# RP2350 register map
Vendor: Raspberry Pi; File version: 0.1
CPU: CM33 r1p0, little endian, MPU, FPU, VTOR, 4 interrupt priority bits, 54 interrupts, 8 SAU regions
Registers are 32-bit, read-write, reset 0x0 unless marked. A register's access mark holds for its fields unless they carry their own. Offsets are from the block's base; [hi:lo] are bit positions; {n}, {i} and the like mark numbered series; 'fields as' and 'values as' point back to an identical list; <NAME> marks a mode.

## RISCV_CSR_BASE_FIXME — CSR listing for Hazard3
Base 0x00000000
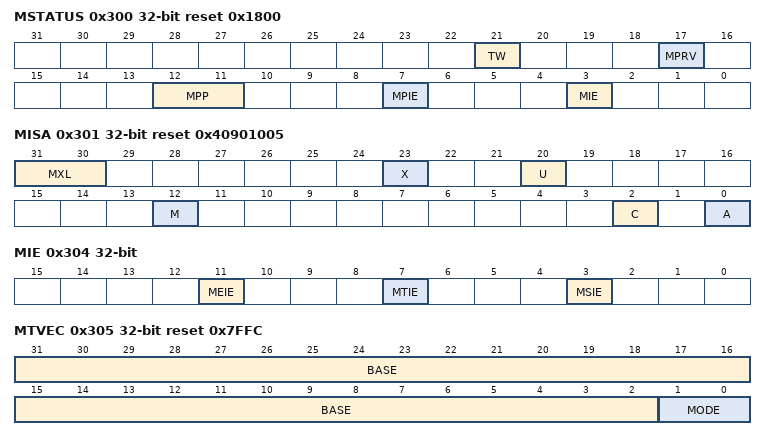
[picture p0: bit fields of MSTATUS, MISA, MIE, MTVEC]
0x300 MSTATUS reset 0x1800 — Machine status register
  [21] TW — Timeout wait. When 1, attempting to execute a WFI instruction in U-mode will instantly cause an illegal instruction exception.
  [17] MPRV — Modify privilege. If 1, loads and stores behave as though the current privilege level were `mpp`. This includes physical memory protection checks, and the privilege level asserted on the system bus alongside the load/store address.
  [12:11] MPP — Previous privilege level. Can store the values 3 (M-mode) or 0 (U-mode). If another value is written, hardware rounds to the nearest supported mode.
  [7] MPIE — Previous interrupt enable. Readable and writable. Is set to the current value of `mstatus.mie` on trap entry. Is set to 1 on trap return.
  [3] MIE — Interrupt enable. Readable and writable. Is set to 0 on trap entry. Is set to the current value of `mstatus.mpie` on trap return.
0x301 MISA ro reset 0x40901005 — Summary of ISA extension support . On RP2350, Hazard3's full `-march` string is: `rv32ima_zicsr_zifencei_zba_zbb_zbs_zbkb_zca_zcb_zcmp` . Note Zca is equivalent to the C extension in this case; all instructions from the RISC-V C extension relevant to a 32-bit non-floating-point processor are supported. On older toolchains which do not support the Zc extensions, the appropriate `-march` string is: `rv32imac_zicsr_zifencei_zba_zbb_zbs_zbkb` . In addition the following custom extensions are configured: Xh3bm, Xh3power, Xh3irq, Xh3pmpm
  [31:30] MXL — Value of 0x1 indicates this is a 32-bit processor.
  [23] X — Value of 1 indicates nonstandard extensions are present. (Xh3b bit manipulation, and custom sleep and interrupt control CSRs)
  [20] U — Value of 1 indicates U-mode is implemented.
  [12] M — Value of 1 indicates the M extension (integer multiply/divide) is implemented.
  [2] C — Value of 1 indicates the C extension (compressed instructions) is implemented.
  [0] A — Value of 1 indicates the A extension (atomics) is implemented.
0x302 MEDELEG — Machine exception delegation register. Not implemented, as no S-mode support.
0x303 MIDELEG — Machine interrupt delegation register. Not implemented, as no S-mode support.
0x304 MIE — Machine interrupt enable register
  [11] MEIE — External interrupt enable. The processor transfers to the external interrupt vector when `mie.meie`, `mip.meip` and `mstatus.mie` are all 1. . Hazard3 has internal registers to individually filter external interrupts (see `meiea`), but this standard control can be used to mask all external interrupts at once.
  [7] MTIE — Timer interrupt enable. The processor transfers to the timer interrupt vector when `mie.mtie`, `mip.mtip` and `mstatus.mie` are all 1, unless a software or external interrupt request is also valid at this time.
  [3] MSIE — Software interrupt enable. The processor transfers to the software interrupt vector `mie.msie`, `mip.msip` and `mstatus.mie` are all 1, unless an external interrupt request is also valid at this time.
0x305 MTVEC reset 0x7FFC — Machine trap handler base address.
  [31:2] BASE — The upper 30 bits of the trap vector address (2 LSBs are implicitly 0). Must be 64-byte-aligned if vectoring is enabled. Otherwise, must be 4-byte-aligned.
  [1:0] MODE — If 0 (direct mode), all traps set pc to the trap vector base. If 1 (vectored), exceptions set pc to the trap vector base, and interrupts set pc to 4 times the interrupt cause (3=soft IRQ, 7=timer IRQ, 11=external IRQ). . The upper bit is hardwired to zero, so attempting to set mode to 2 or 3 will result in a value of 0 or 1 respectively.
    0=Direct entry to mtvec; 1=Vectored entry to a 16-entry jump table starting at mtvec
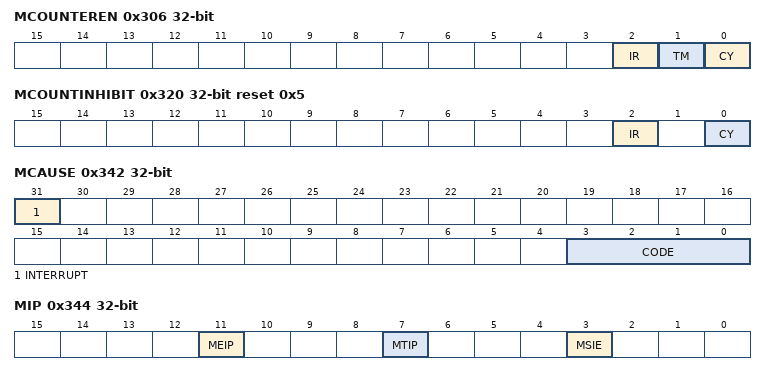
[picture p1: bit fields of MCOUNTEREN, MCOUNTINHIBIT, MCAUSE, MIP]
0x306 MCOUNTEREN — Counter enable. Control access to counters from U-mode. Not to be confused with mcountinhibit.
  [2] IR — If 1, U-mode is permitted to access the `instret`/`instreth` instruction retire counter CSRs. Otherwise, U-mode accesses to these CSRs will trap.
  [1] TM — No hardware effect, as the `time`/`timeh` CSRs are not implemented. However, this field still exists, as M-mode software can use it to track whether it should emulate U-mode attempts to access those CSRs.
  [0] CY — If 1, U-mode is permitted to access the `cycle`/`cycleh` cycle counter CSRs. Otherwise, U-mode accesses to these CSRs will trap.
0x30A MENVCFG ro — Machine environment configuration register, low half
  [0] FIOM — When set, fence instructions in modes less privileged than M-mode which specify that IO memory accesses are ordered will also cause ordering of main memory accesses. . FIOM is hardwired to zero on Hazard3, because S-mode is not supported, and because fence instructions execute as NOPs (with the exception of `fence.i`)
0x310 MSTATUSH ro — High half of mstatus, hardwired to 0.
0x31A MENVCFGH access not given — Machine environment configuration register, high half . This register is fully reserved, as Hazard3 does not implement the relevant extensions. It is implemented as hardwired-0.
0x320 MCOUNTINHIBIT reset 0x5 — Count inhibit register for `mcycle`/`minstret`
  [2] IR — Inhibit counting of the `minstret` and `minstreth` registers. Set by default to save power.
  [0] CY — Inhibit counting of the `mcycle` and `mcycleh` registers. Set by default to save power.
{0x320+i} MHPMEVENT{i} ro (i=3..31) — Extended performance event selector, hardwired to 0.
0x340 MSCRATCH — Scratch register for machine trap handlers. . 32-bit read/write register with no specific hardware function. Software may use this to do a fast save/restore of a core register in a trap handler.
0x341 MEPC — Machine exception program counter. . When entering a trap, the current value of the program counter is recorded here. When executing an `mret`, the processor jumps to `mepc`. Can also be read and written by software.
  [31:2] MEPC
0x342 MCAUSE — Machine trap cause. Set when entering a trap to indicate the reason for the trap. Readable and writable by software.
  [31] INTERRUPT — If 1, the trap was caused by an interrupt. If 0, it was caused by an exception.
  [3:0] CODE — If `interrupt` is set, `code` indicates the index of the bit in mip that caused the trap (3=soft IRQ, 7=timer IRQ, 11=external IRQ). Otherwise, `code` is set according to the cause of the exception.
    0=INSTR_ALIGN (Instruction fetch was misaligned. Will never fire on RP2350, since the C extension is enabled.); 1=INSTR_FAULT (Instruction access fault. Instruction fetch failed a PMP check, or encountered a downstream bus fault, and then passed the point of no speculation.); 2=ILLEGAL_INSTR (Illegal instruction was executed (including illegal CSR accesses)); 3=BREAKPOINT (Breakpoint. An ebreak instruction was executed when the relevant dcsr.ebreak bit was clear.); 4=LOAD_ALIGN (Load address misaligned. Hazard3 requires natural alignment of all accesses.); 5=LOAD_FAULT (Load access fault. A load failed a PMP check, or encountered a downstream bus error.); 6=STORE_ALIGN (Store/AMO address misaligned. Hazard3 requires natural alignment of all accesses.); 7=STORE_FAULT (Store/AMO access fault. A store/AMO failed a PMP check, or encountered a downstream bus error. Also set if an AMO is attempted on a region that does not support atomics (on RP2350, anything but SRAM).); 8=U_ECALL (Environment call from U-mode.); 11=M_ECALL (Environment call from M-mode.)
0x343 MTVAL ro — Machine bad address or instruction. Hardwired to zero.
0x344 MIP access per field — Machine interrupt pending
  [11] MEIP ro — External interrupt pending. The processor transfers to the external interrupt vector when `mie.meie`, `mip.meip` and `mstatus.mie` are all 1. . Hazard3 has internal registers to individually filter which external IRQs appear in `meip`. When `meip` is 1, this indicates there is at least one external interrupt which is asserted (hence pending in `mieipa`), enabled in `meiea`, and of priority greater than or equal to the current preemption level in `meicontext.preempt`.
  [7] MTIP rw — Timer interrupt pending. The processor transfers to the timer interrupt vector when `mie.mtie`, `mip.mtip` and `mstatus.mie` are all 1, unless a software or external interrupt request is also valid at this time.
  [3] MSIE rw — Software interrupt pending. The processor transfers to the software interrupt vector `mie.msie`, `mip.msip` and `mstatus.mie` are all 1, unless an external interrupt request is also valid at this time.
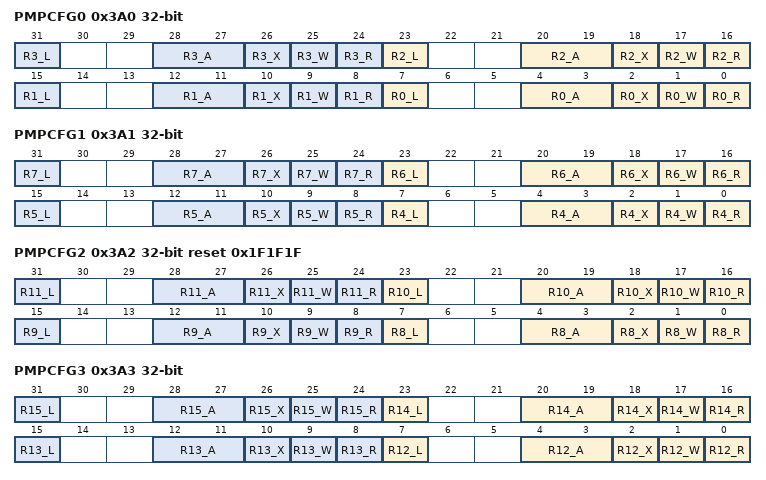
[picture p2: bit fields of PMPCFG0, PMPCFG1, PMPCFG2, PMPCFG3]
0x3A0 PMPCFG0 — Physical memory protection configuration for regions 0 through 3
  [8n+7] R{n}_L (n=0..3) — Lock region {n}, and apply it to M-mode as well as U-mode.
  [8n+4:8n+3] R{n}_A (n=0..3) — Address matching type for region {n}. Writing an unsupported value (TOR) will set the region to OFF.
    0=off (Disable region); 2=na4 (Naturally aligned 4-byte); 3=napot (Naturally aligned power-of-two (8 bytes to 4 GiB))
  [8n+2] R{n}_X (n=0..3) — Execute permission for region {n}
  [8n+1] R{n}_W (n=0..3) — Write permission for region {n}
  [8n] R{n}_R (n=0..3) — Read permission for region {n}
0x3A1 PMPCFG1 — Physical memory protection configuration for regions 4 through 7
  [8n-25] R{n}_L (n=4..7) — Lock region {n}, and apply it to M-mode as well as U-mode.
  [8n-28:8n-29] R{n}_A (n=4..7) — Address matching type for region {n}. Writing an unsupported value (TOR) will set the region to OFF.
    values as PMPCFG0.R0_A
  [8n-30] R{n}_X (n=4..7) — Execute permission for region {n}
  [8n-31] R{n}_W (n=4..7) — Write permission for region {n}
  [8n-32] R{n}_R (n=4..7) — Read permission for region {n}
0x3A2 PMPCFG2 ro reset 0x1F1F1F — Physical memory protection configuration for regions 8 through 11
  [8n-57] R{n}_L (n=8..11) — Lock region {n}, and apply it to M-mode as well as U-mode.
  [8n-60:8n-61] R{n}_A (n=8..11) — Address matching type for region {n}. Writing an unsupported value (TOR) will set the region to OFF.
    values as PMPCFG0.R0_A
  [8n-62] R{n}_X (n=8..11) — Execute permission for region {n}
  [8n-63] R{n}_W (n=8..11) — Write permission for region {n}
  [8n-64] R{n}_R (n=8..11) — Read permission for region {n}
0x3A3 PMPCFG3 ro — Physical memory protection configuration for regions 12 through 15
  [8n-89] R{n}_L (n=12..15) — Lock region {n}, and apply it to M-mode as well as U-mode.
  [8n-92:8n-93] R{n}_A (n=12..15) — Address matching type for region {n}. Writing an unsupported value (TOR) will set the region to OFF.
    values as PMPCFG0.R0_A
  [8n-94] R{n}_X (n=12..15) — Execute permission for region {n}
  [8n-95] R{n}_W (n=12..15) — Write permission for region {n}
  [8n-96] R{n}_R (n=12..15) — Read permission for region {n}
{0x3B0+i} PMPADDR{i} (i=0..7) — Physical memory protection address for region {i}. Note all PMP addresses are in units of four bytes.
  [29:0] PMPADDR{i}
0x3B8 PMPADDR8 ro reset 0x1FFFFFF — Physical memory protection address for region 8. Note all PMP addresses are in units of four bytes. . Hardwired to the address range `0x00000000` through `0x0fffffff`, which contains the boot ROM. This range is made accessible to User mode by default. User mode access to this range can be disabled using one of the dynamically configurable PMP regions, or using the permission registers in ACCESSCTRL.
  [29:0] PMPADDR8
0x3B9 PMPADDR9 ro reset 0x13FFFFFF — Physical memory protection address for region 9. Note all PMP addresses are in units of four bytes. . Hardwired to the address range `0x40000000` through `0x5fffffff`, which contains the system peripherals. This range is made accessible to User mode by default. User mode access to this range can be disabled using one of the dynamically configurable PMP regions, or using the permission registers in ACCESSCTRL.
  [29:0] PMPADDR9
0x3BA PMPADDR10 ro reset 0x35FFFFFF — Physical memory protection address for region 10. Note all PMP addresses are in units of four bytes. . Hardwired to the address range `0xd0000000` through `0xdfffffff`, which contains the core-local peripherals (SIO). This range is made accessible to User mode by default. User mode access to this range can be disabled using one of the dynamically configurable PMP regions, or using the permission registers in ACCESSCTRL.
  [29:0] PMPADDR10
{0x3B0+i} PMPADDR{i} ro (i=11..15) — Physical memory protection address for region {i}. Note all PMP addresses are in units of four bytes. . Hardwired to all-zeroes. This region is not implemented.
  [29:0] PMPADDR{i}
0x7A0 TSELECT — Select trigger to be configured via `tdata1`/`tdata2` . On RP2350, four instruction address triggers are implemented, so only the two LSBs of this register are writable.
  [1:0] TSELECT
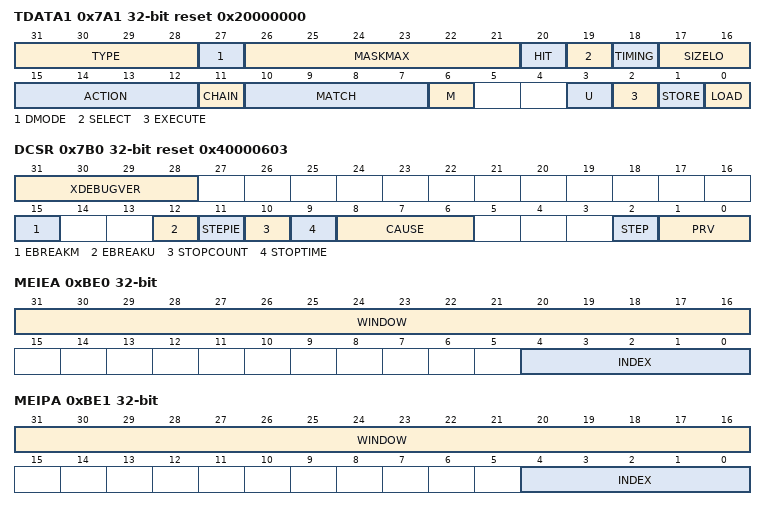
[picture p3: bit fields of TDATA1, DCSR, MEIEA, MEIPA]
0x7A1 TDATA1 access per field reset 0x20000000 — Trigger configuration data 1 . Hazard 3 only supports address/data match triggers (type=2) so this register description includes the `mcontrol` fields for this type. . More precisely, Hazard3 only supports exact instruction address match triggers (hardware breakpoints) so many of this register's fields are hardwired.
  [31:28] TYPE ro — Trigger type. Hardwired to type=2, meaning an address/data match trigger
  [27] DMODE rw — If 0, both Debug and M-mode can write the `tdata` registers at the selected `tselect`. . If 1, only Debug Mode can write the `tdata` registers at the selected `tselect`. Writes from other modes are ignored. . This bit is only writable from Debug Mode
  [26:21] MASKMAX ro — Value of 0 indicates only exact address matches are supported
  [20] HIT ro — Trigger hit flag. Not implemented, hardwired to 0.
  [19] SELECT ro — Hardwired value of 0 indicates that only address matches are supported, not data matches
  [18] TIMING ro — Hardwired value of 0 indicates that trigger fires before the triggering instruction executes, not afterward
  [17:16] SIZELO ro — Hardwired value of 0 indicates that access size matching is not supported
  [15:12] ACTION rw — Select action to be taken when the trigger fires.
    0=ebreak (Raise a breakpoint exception, which can be handled by the M-mode exception handler); 1=debug (Enter debug mode. This action is only selectable when `tdata1.dmode` is 1.)
  [11] CHAIN ro — Hardwired to 0 to indicate trigger chaining is not supported.
  [10:7] MATCH ro — Hardwired to 0 to indicate match is always on the full address specified by `tdata2`
  [6] M rw — When set, enable this trigger in M-mode
  [3] U rw — When set, enable this trigger in U-mode
  [2] EXECUTE rw — When set, the trigger fires on the address of an instruction that is executed.
  [1] STORE ro — Hardwired to 0 to indicate store address/data triggers are not supported
  [0] LOAD ro — Hardwired to 0 to indicate load address/data triggers are not supported
0x7A2 TDATA2 — Trigger configuration data 2 . Contains the address for instruction address triggers (hardware breakpoints)
0x7B0 DCSR access per field reset 0x40000603 — Debug control and status register. Access outside of Debug Mode will cause an illegal instruction exception.
  [31:28] XDEBUGVER ro — Hardwired to 4: external debug support as per RISC-V 0.13.2 debug specification.
  [15] EBREAKM rw — When 1, `ebreak` instructions executed in M-mode will break to Debug Mode instead of trapping
  [12] EBREAKU rw — When 1, `ebreak` instructions executed in U-mode will break to Debug Mode instead of trapping.
  [11] STEPIE ro — Hardwired to 0: no interrupts are taken during hardware single-stepping.
  [10] STOPCOUNT ro — Hardwired to 1: `mcycle`/`mcycleh` and `minstret`/`minstreth` do not increment in Debug Mode.
  [9] STOPTIME ro — Hardwired to 1: core-local timers don't increment in debug mode. External timers (e.g. hart-shared) may be configured to ignore this.
  [8:6] CAUSE ro — Set by hardware when entering debug mode.
    1=ebreak (An ebreak instruction was executed when the relevant `dcsr.ebreakx` bit was set.); 2=trigger (The trigger module caused a breakpoint exception.); 3=haltreq (Processor entered Debug Mode due to a halt request, or a reset-halt request present when the core reset was released.); 4=step (Processor entered Debug Mode after executing one instruction with single-stepping enabled.)
  [2] STEP rw — When 1, re-enter Debug Mode after each instruction executed in M-mode or U-mode.
  [1:0] PRV rw — Read the privilege mode the core was in when entering Debug Mode, and set the privilege mode the core will execute in when returning from Debug Mode.
0x7B1 DPC — Debug program counter. When entering Debug Mode, `dpc` samples the current program counter, e.g. the address of an `ebreak` which caused Debug Mode entry. When leaving debug mode, the processor jumps to `dpc`. The host may read/write this register whilst in Debug Mode.
  [31:1] DPC
0xB00 MCYCLE — Machine-mode cycle counter, low half. Counts up once per cycle, when `mcountinhibit.cy` is 0. Disabled by default to save power.
0xB02 MINSTRET — Machine-mode instruction retire counter, low half. Counts up once per instruction, when `mcountinhibit.ir` is 0. Disabled by default to save power.
{0xB00+i} MHPMCOUNTER{i} ro (i=3..31) — Extended performance counter, hardwired to 0.
0xB80 MCYCLEH — Machine-mode cycle counter, high half. Counts up once per 1 << 32 cycles, when `mcountinhibit.cy` is 0. Disabled by default to save power.
0xB82 MINSTRETH — Machine-mode instruction retire counter, low half. Counts up once per 1 << 32 instructions, when `mcountinhibit.ir` is 0. Disabled by default to save power.
{0xB80+i} MHPMCOUNTER{i}H ro (i=3..31) — Extended performance counter, hardwired to 0.
0xBD0 PMPCFGM0 — PMP M-mode configuration. One bit per PMP region. Setting a bit makes the corresponding region apply to M-mode (like the `pmpcfg.L` bit) but does not lock the region. . PMP is useful for non-security-related purposes, such as stack guarding and peripheral emulation. This extension allows M-mode to freely use any currently unlocked regions for its own purposes, without the inconvenience of having to lock them. . Note that this does not grant any new capabilities to M-mode, since in the base standard it is already possible to apply unlocked regions to M-mode by locking them. In general, PMP regions should be locked in ascending region number order so they can't be subsequently overridden by currently unlocked regions. . Note also that this is not the same as the rule locking bypass bit in the ePMP extension, which does not permit locked and unlocked M-mode regions to coexist. . This is a Hazard3 custom CSR.
  [15:0] PMPCFGM0
0xBE0 MEIEA access per field — External interrupt enable array. . The array contains a read-write bit for each external interrupt request: a `1` bit indicates that interrupt is currently enabled. At reset, all external interrupts are disabled. . If enabled, an external interrupt can cause assertion of the standard RISC-V machine external interrupt pending flag (`mip.meip`), and therefore cause the processor to enter the external interrupt vector. See `meipa`. . There are up to 512 external interrupts. The upper half of this register contains a 16-bit window into the full 512-bit vector. The window is indexed by the 5 LSBs of the write data.
  [31:16] WINDOW rw — 16-bit read/write window into the external interrupt enable array
  [4:0] INDEX wo — Write-only self-clearing field (no value is stored) used to control which window of the array appears in `window`.
0xBE1 MEIPA access per field — External interrupt pending array . Contains a read-only bit for each external interrupt request. Similarly to `meiea`, this register is a window into an array of up to 512 external interrupt flags. The status appears in the upper 16 bits of the value read from `meipa`, and the lower 5 bits of the value _written_ by the same CSR instruction (or 0 if no write takes place) select a 16-bit window of the full interrupt pending array. . A `1` bit indicates that interrupt is currently asserted. IRQs are assumed to be level-sensitive, and the relevant `meipa` bit is cleared by servicing the requestor so that it deasserts its interrupt request. . When any interrupt of sufficient priority is both set in `meipa` and enabled in `meiea`, the standard RISC-V external interrupt pending bit `mip.meip` is asserted. In other words, `meipa` is filtered by `meiea` to generate the standard `mip.meip` flag.
  [31:16] WINDOW ro — 16-bit read-only window into the external interrupt pending array
  [4:0] INDEX wo — Write-only, self-clearing field (no value is stored) used to control which window of the array appears in `window`.
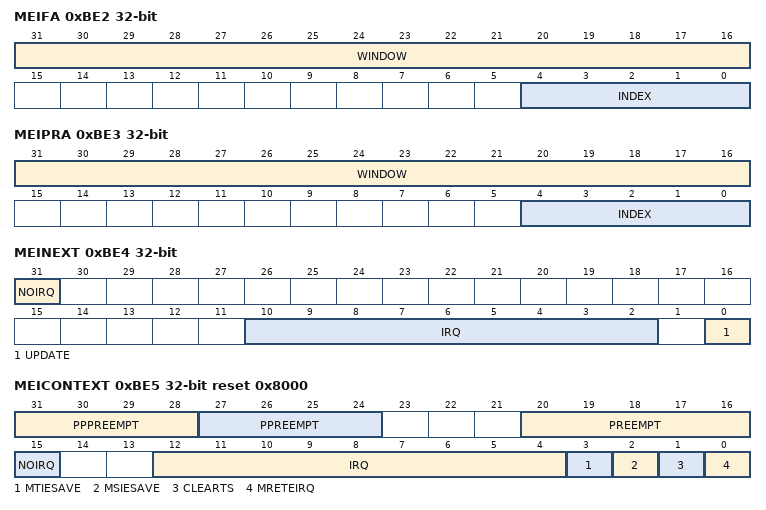
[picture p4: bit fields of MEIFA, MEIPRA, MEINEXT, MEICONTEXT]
0xBE2 MEIFA access per field — External interrupt force array . Contains a read-write bit for every interrupt request. Writing a 1 to a bit in the interrupt force array causes the corresponding bit to become pending in `meipa`. Software can use this feature to manually trigger a particular interrupt. . There are no restrictions on using `meifa` inside of an interrupt. The more useful case here is to schedule some lower-priority handler from within a high-priority interrupt, so that it will execute before the core returns to the foreground code. Implementers may wish to reserve some external IRQs with their external inputs tied to 0 for this purpose. . Bits can be cleared by software, and are cleared automatically by hardware upon a read of `meinext` which returns the corresponding IRQ number in `meinext.irq` with `mienext.noirq` clear (no matter whether `meinext.update` is written). `meifa` implements the same array window indexing scheme as `meiea` and `meipa`.
  [31:16] WINDOW rw — 16-bit read/write window into the external interrupt force array
  [4:0] INDEX wo — Write-only, self-clearing field (no value is stored) used to control which window of the array appears in `window`.
0xBE3 MEIPRA access per field — External interrupt priority array . Each interrupt has an (up to) 4-bit priority value associated with it, and each access to this register reads and/or writes a 16-bit window containing four such priority values. When less than 16 priority levels are available, the LSBs of the priority fields are hardwired to 0. . When an interrupt's priority is lower than the current preemption priority `meicontext.preempt`, it is treated as not being pending for the purposes of `mip.meip`. The pending bit in `meipa` will still assert, but the machine external interrupt pending bit `mip.meip` will not, so the processor will ignore this interrupt. See `meicontext`.
  [31:16] WINDOW rw — 16-bit read/write window into the external interrupt priority array, containing four 4-bit priority values.
  [4:0] INDEX wo — Write-only, self-clearing field (no value is stored) used to control which window of the array appears in `window`.
0xBE4 MEINEXT access per field — Get next external interrupt . Contains the index of the highest-priority external interrupt which is both asserted in `meipa` and enabled in `meiea`, left-shifted by 2 so that it can be used to index an array of 32-bit function pointers. If there is no such interrupt, the MSB is set. . When multiple interrupts of the same priority are both pending and enabled, the lowest-numbered wins. Interrupts with priority less than `meicontext.ppreempt` -- the _previous_ preemption priority -- are treated as though they are not pending. This is to ensure that a preempting interrupt frame does not service interrupts which may be in progress in the frame that was preempted.
  [31] NOIRQ ro — Set when there is no external interrupt which is enabled, pending, and has priority greater than or equal to `meicontext.ppreempt`. Can be efficiently tested with a `bltz` or `bgez` instruction.
  [10:2] IRQ ro — Index of the highest-priority active external interrupt. Zero when no external interrupts with sufficient priority are both pending and enabled.
  [0] UPDATE rw write-clears — Writing 1 (self-clearing) causes hardware to update `meicontext` according to the IRQ number and preemption priority of the interrupt indicated in `noirq`/`irq`. This should be done in a single atomic operation, i.e. `csrrsi a0, meinext, 0x1`.
0xBE5 MEICONTEXT access per field reset 0x8000 — External interrupt context register . Configures the priority level for interrupt preemption, and helps software track which interrupt it is currently in. The latter is useful when a common interrupt service routine handles interrupt requests from multiple instances of the same peripheral. . A three-level stack of preemption priorities is maintained in the `preempt`, `ppreempt` and `pppreempt` fields. The priority stack is saved when hardware enters the external interrupt vector, and restored by an `mret` instruction if `meicontext.mreteirq` is set. . The top entry of the priority stack, `preempt`, is used by hardware to ensure that only higher-priority interrupts can preempt the current interrupt. The next entry, `ppreempt`, is used to avoid servicing interrupts which may already be in progress in a frame that was preempted. The third entry, `pppreempt`, has no hardware effect, but ensures that `preempt` and `ppreempt` can be correctly saved/restored across arbitary levels of preemption.
  [31:28] PPPREEMPT rw — Previous `ppreempt`. Set to `ppreempt` on priority save, set to zero on priority restore. Has no hardware effect, but ensures that when `meicontext` is saved/restored correctly, `preempt` and `ppreempt` stack correctly through arbitrarily many preemption frames.
  [27:24] PPREEMPT rw — Previous `preempt`. Set to `preempt` on priority save, restored to to `pppreempt` on priority restore. . IRQs of lower priority than `ppreempt` are not visible in `meinext`, so that a preemptee is not re-taken in the preempting frame.
  [20:16] PREEMPT rw — Minimum interrupt priority to preempt the current interrupt. Interrupts with lower priority than `preempt` do not cause the core to transfer to an interrupt handler. Updated by hardware when when `meinext.update` is written, or when hardware enters the external interrupt vector. . If an interrupt is present in `meinext` when this field is updated, then `preempt` is set to one level greater than that interrupt's priority. Otherwise, `ppreempt` is set to one level greater than the maximum interrupt priority, disabling preemption.
  [15] NOIRQ rw — Not in interrupt (read/write). Set to 1 at reset. Set to `meinext.noirq` when `meinext.update` is written. No hardware effect.
  [12:4] IRQ rw — Current IRQ number (read/write). Set to `meinext.irq` when `meinext.update` is written. No hardware effect.
  [3] MTIESAVE ro — Reads as the current value of `mie.mtie`, if `clearts` is set by the same CSR access instruction. Otherwise reads as 0. Writes are ORed into `mie.mtie`.
  [2] MSIESAVE ro — Reads as the current value of `mie.msie`, if `clearts` is set by the same CSR access instruction. Otherwise reads as 0. Writes are ORed into `mie.msie`.
  [1] CLEARTS rw write-clears — Write-1 self-clearing field. Writing 1 will clear `mie.mtie` and `mie.msie`, and present their prior values in the `mtiesave` and `msiesave` of this register. This makes it safe to re-enable IRQs (via `mstatus.mie`) without the possibility of being preempted by the standard timer and soft interrupt handlers, which may not be aware of Hazard3's interrupt hardware. . The clear due to `clearts` takes precedence over the set due to `mtiesave`/`msiesave`, although it would be unusual for software to write both on the same cycle.
  [0] MRETEIRQ rw — If 1, enable restore of the preemption priority stack on `mret`. This bit is set on entering the external interrupt vector, cleared by `mret`, and cleared upon taking any trap other than an external interrupt. . Provided `meicontext` is saved on entry to the external interrupt vector (before enabling preemption), is restored before exiting, and the standard software/timer IRQs are prevented from preempting (e.g. by using `clearts`), this flag allows the hardware to safely manage the preemption priority stack even when an external interrupt handler may take exceptions.
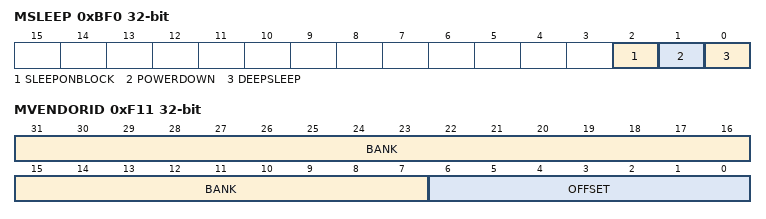
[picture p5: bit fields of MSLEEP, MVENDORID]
0xBF0 MSLEEP — M-mode sleep control register
  [2] SLEEPONBLOCK — Enter the deep sleep state configured by msleep.deepsleep/msleep.powerdown on a `h3.block` instruction, as well as a standard `wfi`. If this bit is clear, a `h3.block` is always implemented as a simple pipeline stall.
  [1] POWERDOWN — Release the external power request when going to sleep. The function of this is platform-defined -- it may do nothing, it may do something simple like clock-gating the fabric, or it may be tied to some complex system-level power controller. . When waking, the processor reasserts its external power-up request, and will not fetch any instructions until the request is acknowledged. This may add considerable latency to the wakeup.
  [0] DEEPSLEEP — Deassert the processor clock enable when entering the sleep state. If a clock gate is instantiated, this allows most of the processor (everything except the power state machine and the interrupt and halt input registers) to be clock gated whilst asleep, which may reduce the sleep current. This adds one cycle to the wakeup latency.
0xBFF DMDATA0 — The Debug Module's DATA0 register is mapped into Hazard3's CSR space so that the Debug Module can exchange data with the core by executing CSR access instructions (this is used to implement the Abstract Access Register command). Only accessible in Debug Mode.
0xC00 CYCLE ro — Read-only U-mode alias of mcycle, accessible when `mcounteren.cy` is set
0xC02 INSTRET ro — Read-only U-mode alias of minstret, accessible when `mcounteren.ir` is set
0xC80 CYCLEH ro — Read-only U-mode alias of mcycleh, accessible when `mcounteren.cy` is set
0xC82 INSTRETH ro — Read-only U-mode alias of minstreth, accessible when `mcounteren.ir` is set
0xF11 MVENDORID ro — Vendor ID
  [31:7] BANK, [6:0] OFFSET
0xF12 MARCHID ro reset 0x1B — Architecture ID (Hazard3)
0xF13 MIMPID ro — Implementation ID
0xF14 MHARTID ro — Hardware thread ID. On RP2350, core 0 has a hart ID of 0, and core 1 has a hart ID of 1.
0xF15 MCONFIGPTR ro — Pointer to configuration data structure (hardwired to 0)

## Notices in the file
Copyright (c) 2022 Raspberry Pi (Trading) Ltd.
SPDX-License-Identifier: BSD-3-Clause
